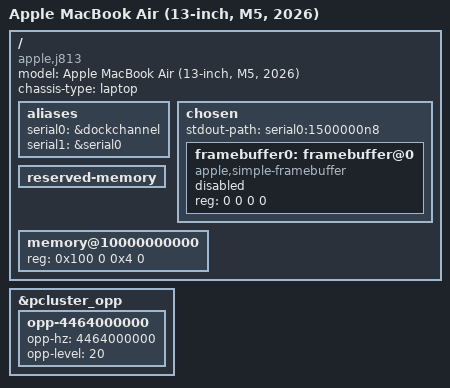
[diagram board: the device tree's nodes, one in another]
// SPDX-License-Identifier: GPL-2.0+ OR MIT
/*
 * Apple MacBook Air (13-inch, M5, 2026), J813.
 *
 * Initial RAM boot resources measured from the J813 Apple Device Tree.
 * The loader supplies usable memory, CPU release addresses and framebuffer
 * geometry. Peripheral power management is left with the boot firmware.
 */
/dts-v1/;

#include "t8142.dtsi"

/ {
	compatible = "apple,j813", "apple,t8142", "apple,arm-platform";
	model = "Apple MacBook Air (13-inch, M5, 2026)";
	chassis-type = "laptop";

	aliases {
		serial0 = &dockchannel;
		serial1 = &serial0;
	};

	chosen {
		#address-cells = <2>;
		#size-cells = <2>;
		ranges;

		stdout-path = "serial0:1500000n8";

		framebuffer0: framebuffer@0 {
			compatible = "apple,simple-framebuffer", "simple-framebuffer";
			reg = <0 0 0 0>; /* Filled by the loader. */
			status = "disabled";
		};
	};

	reserved-memory {
		#address-cells = <2>;
		#size-cells = <2>;
		ranges;
		/* Filled by the loader. */
	};

	memory@10000000000 {
		device_type = "memory";
		reg = <0x100 0 0x4 0>; /* Filled by the loader. */
	};
};

/*
 * ADT voltage-states5-sram level 20; level 19 (4416 MHz) is below level 18
 * and left out. Cap each cluster at its measured J813 firmware handoff state.
 */
&pcluster_opp {
	opp-4464000000 {
		opp-hz = /bits/ 64 <4464000000>;
		opp-level = <20>;
	};
};

#include "t8142-j813-gpu.dtsi"
#include "t8142-j813-peripherals.dtsi"
#include "t8142-j813-usb.dtsi"
#include "t8142-j813-display.dtsi"
#include "t8142-j813-isp.dtsi"
#include "t8142-j813-psci-idle.dtsi"
#include "t8142-j813-n1.dtsi"
#include "t8142-j813-audio.dtsi"
